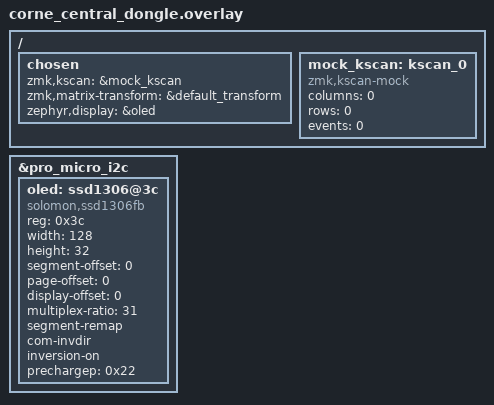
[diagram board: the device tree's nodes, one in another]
/*
 * Copyright (c) 2020 Pete Johanson
 *
 * SPDX-License-Identifier: MIT
 */

#include "corne.dtsi"

/ {
    chosen {
        zmk,kscan = &mock_kscan;
        zmk,matrix-transform = &default_transform;
        zephyr,display = &oled;
    };

    mock_kscan: kscan_0 {
        compatible = "zmk,kscan-mock";
        columns = <0>;
        rows = <0>;
        events = <0>;
    };
};

&pro_micro_i2c {
    status = "okay";
    oled: ssd1306@3c {
        compatible = "solomon,ssd1306fb";
        reg = <0x3c>;
        width = <128>;
        height = <32>;
        segment-offset = <0>;
        page-offset = <0>;
        display-offset = <0>;
        multiplex-ratio = <31>;
        segment-remap;
        com-invdir;
        inversion-on;
        prechargep = <0x22>;
    };
}; 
